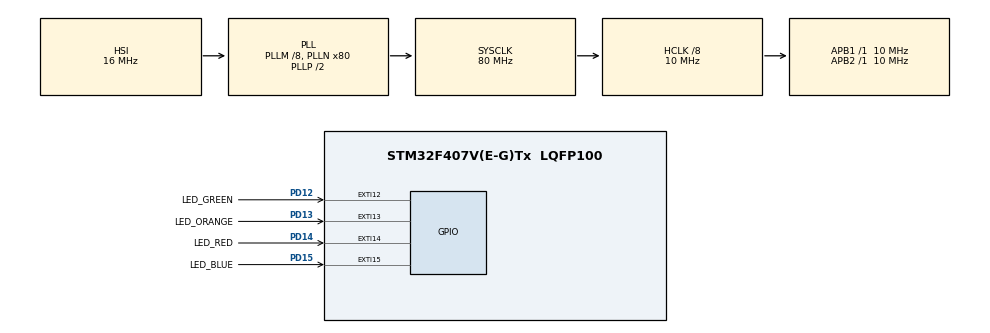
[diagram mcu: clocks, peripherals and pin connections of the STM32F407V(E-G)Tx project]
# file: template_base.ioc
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Mcu.Family=STM32F4
Mcu.Name=STM32F407V(E-G)Tx
Mcu.Package=LQFP100
NVIC.PriorityGroup=NVIC_PRIORITYGROUP_4
PD12.GPIO_Label=LED_GREEN
PD12.Signal=GPXTI12
PD13.GPIO_Label=LED_ORANGE
PD13.Signal=GPXTI13
PD14.GPIO_Label=LED_RED
PD14.Signal=GPXTI14
PD15.GPIO_Label=LED_BLUE
PD15.Signal=GPXTI15
ProjectManager.HeapSize=0x200
ProjectManager.StackSize=0x400
ProjectManager.TargetToolchain=Makefile
RCC.48MHZClocksFreq_Value=40000000
RCC.AHBCLKDivider=RCC_SYSCLK_DIV8
RCC.AHBFreq_Value=10000000
RCC.APB1Freq_Value=10000000
RCC.APB1TimFreq_Value=10000000
RCC.APB2Freq_Value=10000000
RCC.APB2TimFreq_Value=10000000
RCC.CortexFreq_Value=10000000
RCC.HCLKFreq_Value=10000000
RCC.HSE_VALUE=25000000
RCC.HSI_VALUE=16000000
RCC.LSE_VALUE=32768
RCC.PLLM=8
RCC.PLLN=80
RCC.SYSCLKFreq_VALUE=80000000
RCC.SYSCLKSource=RCC_SYSCLKSOURCE_PLLCLK
RCC.VCOOutputFreq_Value=160000000
board=custom

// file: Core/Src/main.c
/* USER CODE BEGIN Header */
/**
  ******************************************************************************
  * @file           : main.c
  * @brief          : Main program body
  ******************************************************************************
  * @attention
  *
  * Copyright (c) 2024 STMicroelectronics.
  * All rights reserved.
  *
  * This software is licensed under terms that can be found in the LICENSE file
  * in the root directory of this software component.
  * If no LICENSE file comes with this software, it is provided AS-IS.
  *
  ******************************************************************************
  */
/* USER CODE END Header */
#include "main.h"
#include <FreeRTOS.h>
#include <task.h>

void SystemClock_Config(void);
static void MX_GPIO_Init(void);

/* USER CODE BEGIN 0 */

void   prvSetupHardware(){
 HAL_Init();
 SystemClock_Config();
 MX_GPIO_Init();

}

void vApplicationStackOverflowHook( TaskHandle_t xTask,
                                    char * pcTaskName )
{
    // Si tengo overflow activo el hook
    ( void ) xTask;
    ( void ) pcTaskName;
}

/* USER CODE END 0 */

int main(void)
{

  prvSetupHardware();

  vTaskStartScheduler();
  /* Infinite loop */
  while (1)
  {

  }
}

void SystemClock_Config(void)
{
  RCC_OscInitTypeDef RCC_OscInitStruct = {0};
  RCC_ClkInitTypeDef RCC_ClkInitStruct = {0};

  /** Configure the main internal regulator output voltage
  */
  __HAL_RCC_PWR_CLK_ENABLE();
  __HAL_PWR_VOLTAGESCALING_CONFIG(PWR_REGULATOR_VOLTAGE_SCALE1);

  /** Initializes the RCC Oscillators according to the specified parameters
  * in the RCC_OscInitTypeDef structure.
  */
  RCC_OscInitStruct.OscillatorType = RCC_OSCILLATORTYPE_HSI;
  RCC_OscInitStruct.HSIState = RCC_HSI_ON;
  RCC_OscInitStruct.HSICalibrationValue = RCC_HSICALIBRATION_DEFAULT;
  RCC_OscInitStruct.PLL.PLLState = RCC_PLL_ON;
  RCC_OscInitStruct.PLL.PLLSource = RCC_PLLSOURCE_HSI;
  RCC_OscInitStruct.PLL.PLLM = 8;
  RCC_OscInitStruct.PLL.PLLN = 80;
  RCC_OscInitStruct.PLL.PLLP = RCC_PLLP_DIV2;
  RCC_OscInitStruct.PLL.PLLQ = 4;
  if (HAL_RCC_OscConfig(&RCC_OscInitStruct) != HAL_OK)
  {
    Error_Handler();
  }

  /** Initializes the CPU, AHB and APB buses clocks
  */
  RCC_ClkInitStruct.ClockType = RCC_CLOCKTYPE_HCLK|RCC_CLOCKTYPE_SYSCLK
                              |RCC_CLOCKTYPE_PCLK1|RCC_CLOCKTYPE_PCLK2;
  RCC_ClkInitStruct.SYSCLKSource = RCC_SYSCLKSOURCE_PLLCLK;
  RCC_ClkInitStruct.AHBCLKDivider = RCC_SYSCLK_DIV8;
  RCC_ClkInitStruct.APB1CLKDivider = RCC_HCLK_DIV1;
  RCC_ClkInitStruct.APB2CLKDivider = RCC_HCLK_DIV1;

  if (HAL_RCC_ClockConfig(&RCC_ClkInitStruct, FLASH_LATENCY_0) != HAL_OK)
  {
    Error_Handler();
  }
}

static void MX_GPIO_Init(void)
{
  GPIO_InitTypeDef GPIO_InitStruct = {0};

  /* GPIO Ports Clock Enable */
  __HAL_RCC_GPIOD_CLK_ENABLE();

  /*Configure GPIO pins : LED_GREEN_Pin LED_ORANGE_Pin LED_RED_Pin LED_BLUE_Pin */
  GPIO_InitStruct.Pin = LED_GREEN_Pin|LED_ORANGE_Pin|LED_RED_Pin|LED_BLUE_Pin;
  GPIO_InitStruct.Mode = GPIO_MODE_IT_RISING;
  GPIO_InitStruct.Pull = GPIO_NOPULL;
  HAL_GPIO_Init(GPIOD, &GPIO_InitStruct);

}

void Error_Handler(void)
{
  __disable_irq();
  while (1)
  {
  }
}
